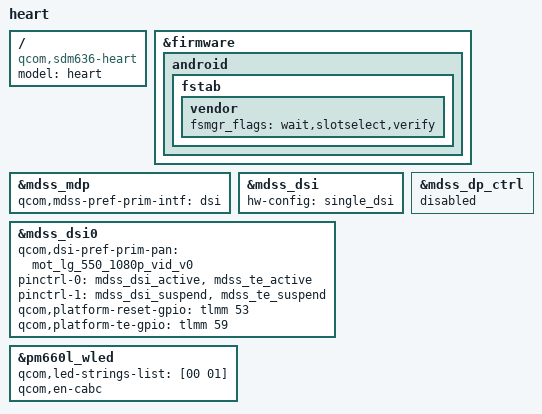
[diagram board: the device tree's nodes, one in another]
/* Copyright (c) 2016, Motorola Mobility Inc. All rights reserved.
 *
 * This program is free software; you can redistribute it and/or modify
 * it under the terms of the GNU General Public License version 2 and
 * only version 2 as published by the Free Software Foundation.
 *
 * This program is distributed in the hope that it will be useful,
 * but WITHOUT ANY WARRANTY; without even the implied warranty of
 * MERCHANTABILITY or FITNESS FOR A PARTICULAR PURPOSE.  See the
 * GNU General Public License for more details.
 */

#include "sdm636-moto-common.dtsi"
#include "dsi-panel-mot-lg-550-1080p-vid.dtsi"

#include "dsi-panel-mot-tianma-520-1080p-vid.dtsi"
#include "dsi-panel-mot-boe-520-1080p-vid.dtsi"

/ {
	model = "heart";
	compatible = "qcom,sdm636-heart", "qcom,sdm636-moto", "qcom,sdm636";
};

&firmware {
	android {
		fstab {
			vendor {
				fsmgr_flags = "wait,slotselect,verify";
			};
		};
	};
};
&mdss_mdp {
	qcom,mdss-pref-prim-intf = "dsi";
};

&mdss_dsi {
	hw-config = "single_dsi";
};

&mdss_dsi0 {
	qcom,dsi-pref-prim-pan = <&mot_lg_550_1080p_vid_v0>;
	pinctrl-names = "mdss_default", "mdss_sleep";
	pinctrl-0 = <&mdss_dsi_active &mdss_te_active>;
	pinctrl-1 = <&mdss_dsi_suspend &mdss_te_suspend>;
	qcom,platform-reset-gpio = <&tlmm 53 0>;
	qcom,platform-te-gpio = <&tlmm 59 0>;
};

&pm660l_wled {
	qcom,led-strings-list = [00 01];
	qcom,en-cabc;
	/delete-property/ qcom,auto-calibration-enable;
};

&mdss_dp_ctrl{
		status = "disabled";
};
